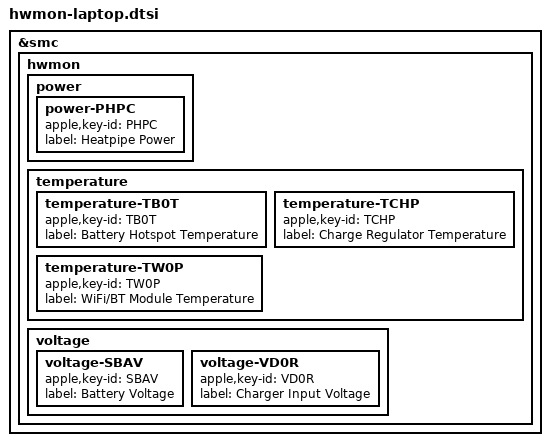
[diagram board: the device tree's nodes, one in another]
// SPDX-License-Identifier: GPL-2.0-or-later OR MIT
/*
 * Hardware monitoring sensors expected on all Apple Silicon laptops
 *
 * Copyright The Asahi Linux Contributors
 */

&smc {
	hwmon {
		power {
			power-PHPC {
				apple,key-id = "PHPC";
				label = "Heatpipe Power";
			};
		};

		temperature {
			temperature-TB0T {
				apple,key-id = "TB0T";
				label = "Battery Hotspot Temperature";
			};
			temperature-TCHP {
				apple,key-id = "TCHP";
				label = "Charge Regulator Temperature";
			};
			temperature-TW0P {
				apple,key-id = "TW0P";
				label = "WiFi/BT Module Temperature";
			};
		};

		voltage {
			voltage-SBAV {
				apple,key-id = "SBAV";
				label = "Battery Voltage";
			};
			voltage-VD0R {
				apple,key-id = "VD0R";
				label = "Charger Input Voltage";
			};
		};
	};
};
